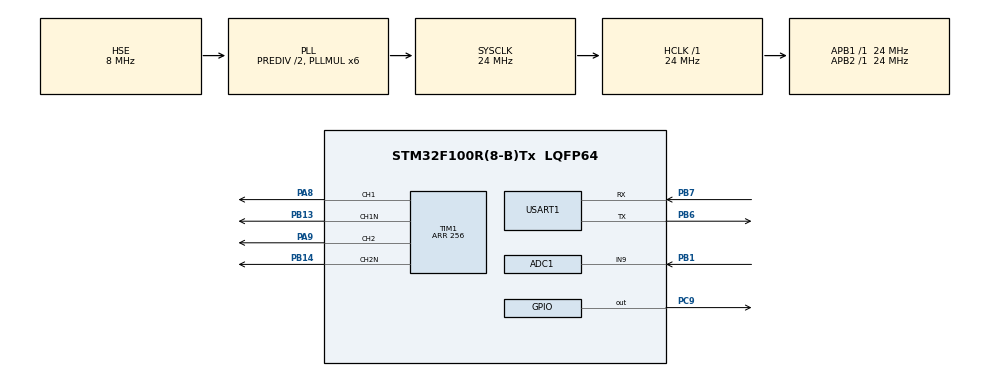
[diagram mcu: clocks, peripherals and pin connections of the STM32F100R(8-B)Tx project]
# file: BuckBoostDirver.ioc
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ADC1.Channel-6\#ChannelRegularConversion=ADC_CHANNEL_9
ADC1.Rank-6\#ChannelRegularConversion=1
ADC1.SamplingTime-6\#ChannelRegularConversion=ADC_SAMPLETIME_7CYCLES_5
ADC1.master=1
FREERTOS.Tasks01=defaultTask,0,128,StartDefaultTask
Mcu.Family=STM32F1
Mcu.Name=STM32F100R(8-B)Tx
Mcu.Package=LQFP64
NVIC.PriorityGroup=NVIC_PRIORITYGROUP_4
PA13.Mode=Serial_Wire
PA13.Signal=SYS_JTMS-SWDIO
PA14.Mode=Serial_Wire
PA14.Signal=SYS_JTCK-SWCLK
PA8.GPIO_ModeDefaultPP=GPIO_MODE_AF_PP
PA8.GPIO_Speed=GPIO_SPEED_LOW
PA8.Signal=S_TIM1_CH1
PA9.GPIO_ModeDefaultPP=GPIO_MODE_AF_PP
PA9.GPIO_Speed=GPIO_SPEED_LOW
PA9.Signal=S_TIM1_CH2
PB1.Signal=ADCx_IN9
PB13.GPIO_ModeDefaultPP=GPIO_MODE_AF_PP
PB13.GPIO_Speed=GPIO_SPEED_LOW
PB13.Mode=PWM Generation1 CH1 CH1N
PB13.Signal=TIM1_CH1N
PB14.GPIO_ModeDefaultPP=GPIO_MODE_AF_PP
PB14.GPIO_Speed=GPIO_SPEED_LOW
PB14.Mode=PWM Generation2 CH2 CH2N
PB14.Signal=TIM1_CH2N
PB6.Mode=Asynchronous
PB6.Signal=USART1_TX
PB7.Mode=Asynchronous
PB7.Signal=USART1_RX
PC9.Signal=GPIO_Output
PD0-OSC_IN.Mode=HSE-External-Oscillator
PD0-OSC_IN.Signal=RCC_OSC_IN
PD1-OSC_OUT.Mode=HSE-External-Oscillator
PD1-OSC_OUT.Signal=RCC_OSC_OUT
ProjectManager.TargetToolchain=EWARM
RCC.AHBFreq_Value=24000000
RCC.APB1Freq_Value=24000000
RCC.APB1TimFreq_Value=24000000
RCC.APB2Freq_Value=24000000
RCC.APB2TimFreq_Value=24000000
RCC.HCLKFreq_Value=24000000
RCC.HSEDivPLL=RCC_HSE_PREDIV_DIV2
RCC.PLLMUL=RCC_PLL_MUL6
RCC.PLLSource=RCC_PLLSOURCE_HSE
RCC.SYSCLKFreq_VALUE=24000000
RCC.SYSCLKSource=RCC_SYSCLKSOURCE_PLLCLK
SH.ADCx_IN9.0=ADC1_IN9,IN9
SH.S_TIM1_CH1.0=TIM1_CH1,PWM Generation1 CH1 CH1N
SH.S_TIM1_CH2.0=TIM1_CH2,PWM Generation2 CH2 CH2N
TIM1.AutomaticOutput=TIM_AUTOMATICOUTPUT_ENABLE
TIM1.Channel-PWM\ Generation2\ CH2\ CH2N=TIM_CHANNEL_2
TIM1.DeadTime=1
TIM1.Period=256
TIM1.Pulse-PWM\ Generation1\ CH1\ CH1N=128
VP_ADC1_Vref_Input.Mode=IN-Vrefint
VP_FREERTOS_VS_ENABLE.Mode=Enabled
VP_TIM1_VS_ClockSourceINT.Mode=Internal

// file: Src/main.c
/**
  ******************************************************************************
  * File Name          : main.c
  * Date               : 27/05/2015 15:28:59
  * Description        : Main program body
  ******************************************************************************
  *
  * COPYRIGHT(c) 2015 STMicroelectronics
  *
  * Redistribution and use in source and binary forms, with or without modification,
  * are permitted provided that the following conditions are met:
  *   1. Redistributions of source code must retain the above copyright notice,
  *      this list of conditions and the following disclaimer.
  *   2. Redistributions in binary form must reproduce the above copyright notice,
  *      this list of conditions and the following disclaimer in the documentation
  *      and/or other materials provided with the distribution.
  *   3. Neither the name of STMicroelectronics nor the names of its contributors
  *      may be used to endorse or promote products derived from this software
  *      without specific prior written permission.
  *
  * THIS SOFTWARE IS PROVIDED BY THE COPYRIGHT HOLDERS AND CONTRIBUTORS "AS IS"
  * AND ANY EXPRESS OR IMPLIED WARRANTIES, INCLUDING, BUT NOT LIMITED TO, THE
  * IMPLIED WARRANTIES OF MERCHANTABILITY AND FITNESS FOR A PARTICULAR PURPOSE ARE
  * DISCLAIMED. IN NO EVENT SHALL THE COPYRIGHT HOLDER OR CONTRIBUTORS BE LIABLE
  * FOR ANY DIRECT, INDIRECT, INCIDENTAL, SPECIAL, EXEMPLARY, OR CONSEQUENTIAL
  * DAMAGES (INCLUDING, BUT NOT LIMITED TO, PROCUREMENT OF SUBSTITUTE GOODS OR
  * SERVICES; LOSS OF USE, DATA, OR PROFITS; OR BUSINESS INTERRUPTION) HOWEVER
  * CAUSED AND ON ANY THEORY OF LIABILITY, WHETHER IN CONTRACT, STRICT LIABILITY,
  * OR TORT (INCLUDING NEGLIGENCE OR OTHERWISE) ARISING IN ANY WAY OUT OF THE USE
  * OF THIS SOFTWARE, EVEN IF ADVISED OF THE POSSIBILITY OF SUCH DAMAGE.
  *
  ******************************************************************************
  */

#include "stm32f1xx_hal.h"
#include "cmsis_os.h"

ADC_HandleTypeDef hadc1;

TIM_HandleTypeDef htim1;

UART_HandleTypeDef huart1;

osThreadId defaultTaskHandle;

void SystemClock_Config(void);
static void MX_GPIO_Init(void);
static void MX_ADC1_Init(void);
static void MX_TIM1_Init(void);
static void MX_USART1_UART_Init(void);
void StartDefaultTask(void const * argument);

int main(void)
{

  /* MCU Configuration----------------------------------------------------------*/

  /* Reset of all peripherals, Initializes the Flash interface and the Systick. */
  HAL_Init();

  /* Configure the system clock */
  SystemClock_Config();

  /* Initialize all configured peripherals */
  MX_GPIO_Init();
  MX_ADC1_Init();
  MX_TIM1_Init();
  MX_USART1_UART_Init();

  /* Create the thread(s) */
  /* definition and creation of defaultTask */
  osThreadDef(defaultTask, StartDefaultTask, osPriorityNormal, 0, 128);
  defaultTaskHandle = osThreadCreate(osThread(defaultTask), NULL);

  /* Start scheduler */
  osKernelStart();

  /* We should never get here as control is now taken by the scheduler */

  /* Infinite loop */
  while (1)
  {

  }

}

/** System Clock Configuration
*/
void SystemClock_Config(void)
{

  RCC_OscInitTypeDef RCC_OscInitStruct;
  RCC_ClkInitTypeDef RCC_ClkInitStruct;
  RCC_PeriphCLKInitTypeDef PeriphClkInit;

  RCC_OscInitStruct.OscillatorType = RCC_OSCILLATORTYPE_HSE;
  RCC_OscInitStruct.HSEState = RCC_HSE_ON;
  RCC_OscInitStruct.HSEPredivValue = RCC_HSE_PREDIV_DIV2;
  RCC_OscInitStruct.PLL.PLLState = RCC_PLL_ON;
  RCC_OscInitStruct.PLL.PLLSource = RCC_PLLSOURCE_HSE;
  RCC_OscInitStruct.PLL.PLLMUL = RCC_PLL_MUL6;
  HAL_RCC_OscConfig(&RCC_OscInitStruct);

  RCC_ClkInitStruct.ClockType = RCC_CLOCKTYPE_SYSCLK;
  RCC_ClkInitStruct.SYSCLKSource = RCC_SYSCLKSOURCE_PLLCLK;
  RCC_ClkInitStruct.AHBCLKDivider = RCC_SYSCLK_DIV1;
  RCC_ClkInitStruct.APB1CLKDivider = RCC_HCLK_DIV1;
  RCC_ClkInitStruct.APB2CLKDivider = RCC_HCLK_DIV1;
  HAL_RCC_ClockConfig(&RCC_ClkInitStruct, FLASH_LATENCY_0);

  PeriphClkInit.PeriphClockSelection = RCC_PERIPHCLK_ADC;
  PeriphClkInit.AdcClockSelection = RCC_ADCPCLK2_DIV2;
  HAL_RCCEx_PeriphCLKConfig(&PeriphClkInit);

}

/* ADC1 init function */
void MX_ADC1_Init(void)
{

  ADC_ChannelConfTypeDef sConfig;

    /**Common config
    */
  hadc1.Instance = ADC1;
  hadc1.Init.ScanConvMode = ADC_SCAN_DISABLE;
  hadc1.Init.ContinuousConvMode = DISABLE;
  hadc1.Init.DiscontinuousConvMode = DISABLE;
  hadc1.Init.ExternalTrigConv = ADC_SOFTWARE_START;
  hadc1.Init.DataAlign = ADC_DATAALIGN_RIGHT;
  hadc1.Init.NbrOfConversion = 1;
  HAL_ADC_Init(&hadc1);

    /**Configure Regular Channel
    */
  sConfig.Channel = ADC_CHANNEL_9;
  sConfig.Rank = 1;
  sConfig.SamplingTime = ADC_SAMPLETIME_7CYCLES_5;
  HAL_ADC_ConfigChannel(&hadc1, &sConfig);

}

/* TIM1 init function */
void MX_TIM1_Init(void)
{

  TIM_ClockConfigTypeDef sClockSourceConfig;
  TIM_MasterConfigTypeDef sMasterConfig;
  TIM_BreakDeadTimeConfigTypeDef sBreakDeadTimeConfig;
  TIM_OC_InitTypeDef sConfigOC;

  htim1.Instance = TIM1;
  htim1.Init.Prescaler = 0;
  htim1.Init.CounterMode = TIM_COUNTERMODE_UP;
  htim1.Init.Period = 256;
  htim1.Init.ClockDivision = TIM_CLOCKDIVISION_DIV1;
  htim1.Init.RepetitionCounter = 0;
  HAL_TIM_Base_Init(&htim1);

  sClockSourceConfig.ClockSource = TIM_CLOCKSOURCE_INTERNAL;
  HAL_TIM_ConfigClockSource(&htim1, &sClockSourceConfig);

  HAL_TIM_PWM_Init(&htim1);

  sMasterConfig.MasterOutputTrigger = TIM_TRGO_RESET;
  sMasterConfig.MasterSlaveMode = TIM_MASTERSLAVEMODE_DISABLE;
  HAL_TIMEx_MasterConfigSynchronization(&htim1, &sMasterConfig);

  sBreakDeadTimeConfig.OffStateRunMode = TIM_OSSR_DISABLE;
  sBreakDeadTimeConfig.OffStateIDLEMode = TIM_OSSI_DISABLE;
  sBreakDeadTimeConfig.LockLevel = TIM_LOCKLEVEL_OFF;
  sBreakDeadTimeConfig.DeadTime = 1;
  sBreakDeadTimeConfig.BreakState = TIM_BREAK_DISABLE;
  sBreakDeadTimeConfig.BreakPolarity = TIM_BREAKPOLARITY_HIGH;
  sBreakDeadTimeConfig.AutomaticOutput = TIM_AUTOMATICOUTPUT_ENABLE;
  HAL_TIMEx_ConfigBreakDeadTime(&htim1, &sBreakDeadTimeConfig);

  sConfigOC.OCMode = TIM_OCMODE_PWM1;
  sConfigOC.Pulse = 128;
  sConfigOC.OCPolarity = TIM_OCPOLARITY_HIGH;
  sConfigOC.OCNPolarity = TIM_OCNPOLARITY_HIGH;
  sConfigOC.OCFastMode = TIM_OCFAST_DISABLE;
  sConfigOC.OCIdleState = TIM_OCIDLESTATE_RESET;
  sConfigOC.OCNIdleState = TIM_OCNIDLESTATE_RESET;
  HAL_TIM_PWM_ConfigChannel(&htim1, &sConfigOC, TIM_CHANNEL_1);

  sConfigOC.Pulse = 0;
  HAL_TIM_PWM_ConfigChannel(&htim1, &sConfigOC, TIM_CHANNEL_2);
  HAL_TIM_Base_Start(&htim1);

  HAL_TIM_PWM_Start(&htim1, TIM_CHANNEL_1);

}

/* USART1 init function */
void MX_USART1_UART_Init(void)
{

  huart1.Instance = USART1;
  huart1.Init.BaudRate = 115200;
  huart1.Init.WordLength = UART_WORDLENGTH_8B;
  huart1.Init.StopBits = UART_STOPBITS_1;
  huart1.Init.Parity = UART_PARITY_NONE;
  huart1.Init.Mode = UART_MODE_TX_RX;
  huart1.Init.HwFlowCtl = UART_HWCONTROL_NONE;
  huart1.Init.OverSampling = UART_OVERSAMPLING_16;
  HAL_UART_Init(&huart1);

}

/** Configure pins as
        * Analog
        * Input
        * Output
        * EVENT_OUT
        * EXTI
*/
void MX_GPIO_Init(void)
{

  GPIO_InitTypeDef GPIO_InitStruct;

  /* GPIO Ports Clock Enable */
  __GPIOD_CLK_ENABLE();
  __GPIOB_CLK_ENABLE();
  __GPIOC_CLK_ENABLE();
  __GPIOA_CLK_ENABLE();

  /*Configure GPIO pin : PC9 */
  GPIO_InitStruct.Pin = GPIO_PIN_9;
  GPIO_InitStruct.Mode = GPIO_MODE_OUTPUT_PP;
  GPIO_InitStruct.Speed = GPIO_SPEED_LOW;
  HAL_GPIO_Init(GPIOC, &GPIO_InitStruct);

}

/* StartDefaultTask function */
void StartDefaultTask(void const * argument)
{

  /* USER CODE BEGIN 5 */
  /* Infinite loop */
  for(;;)
  {
    osDelay(300);
    HAL_GPIO_TogglePin(GPIOC, GPIO_PIN_9);
  }
  /* USER CODE END 5 */
}

/************************ (C) COPYRIGHT STMicroelectronics *****END OF FILE****/
